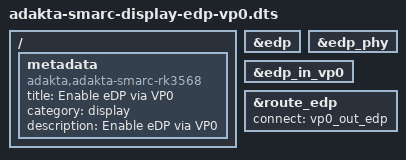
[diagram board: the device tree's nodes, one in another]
/dts-v1/;
/plugin/;

/ {
	metadata {
		title = "Enable eDP via VP0";
		compatible = "adakta,adakta-smarc-rk3568";
		category = "display";
		description = "Enable eDP via VP0";
	};

	fragment@0 {
		target = <&edp>;

		__overlay__ {
			status = "okay";
		};
	};

	fragment@1 {
		target = <&edp_phy>;

		__overlay__ {
			status = "okay";
		};
	};

	fragment@2 {
		target = <&edp_in_vp0>;

		__overlay__ {
			status = "okay";
		};
	};

	fragment@3 {
		target = <&route_edp>;

		__overlay__ {
			status = "okay";
			connect = <&vp0_out_edp>;
		};
	};
};
